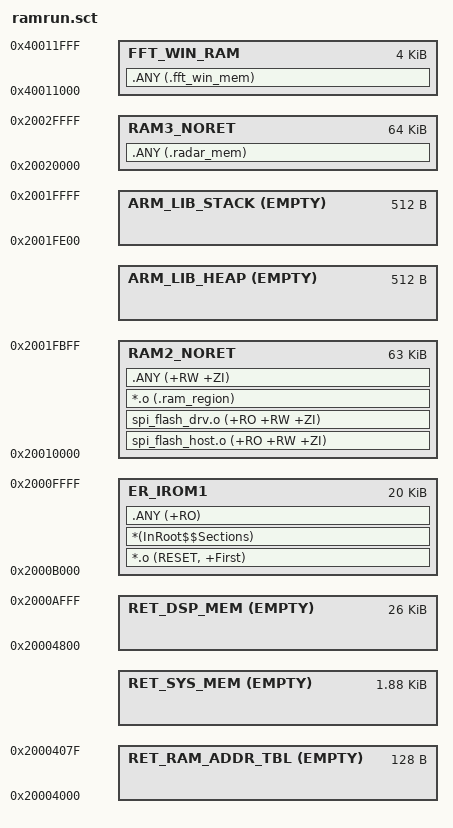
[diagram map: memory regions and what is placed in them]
#! armclang -E --target=arm-arm-none-eabi -mcpu=cortex-m0plus -xc
; *************************************************************
; *** Scatter-Loading Description File generated by uVision ***
; *************************************************************

#define STACK_SIZE        0x200
#define HEAP_SIZE         0x200

; SRAM0 0x2000_4000 -->   0x2000_8000 (ret_ram_tbl, SYS_MEM, DSP_MEM)
#define SRAM0_16KB_BASE   0x20004000
#define SRAM0_16KB_SIZE   0x4000

; 128 = 32*4, ret_ram_tbl can have 32 items at most
#define RET_RAM_TBL_BASE  SRAM0_16KB_BASE
#define RET_RAM_TBL_SIZE  128

#define RET_SYS_MEM_BASE  (RET_RAM_TBL_BASE + RET_RAM_TBL_SIZE)
#define RET_SYS_MEM_SIZE  (0x800 - RET_RAM_TBL_SIZE)

#define RET_DSP_MEM_BASE  0x20004800
#define RET_DSP_MEM_SIZE  0x6800

; SRAM1 0x2000_8000 -->   0x2001_0000 (Code)
#define FLASH_BASE        0x2000b000
#define FLASE_SIZE        0x00005000

; SRAM2 0x2001_0000 -->   0x2002_0000 (NO Retention, 64KB)
#define RAM2_NORET_BASE    0x20010000
#define RAM2_NORET_SIZE    0x00010000

; SRAM3 0x2002_0000 -->   0x2003_0000 (NO Retention, 64KB)
#define RAM3_NORET_BASE    0x20020000
#define RAM3_NORET_SIZE    0x00010000

; DSP FFT Win Rame (DSP occupies only)
#define FFT_WIN_BASE      0x40011000
#define FFT_WIN_SIZE      0x00001000

LR_IROM1 FLASH_BASE FLASE_SIZE  {    ; load region size_region
  ER_IROM1 FLASH_BASE FLASE_SIZE  {  ; load address = execution address
   *.o (RESET, +First)
   *(InRoot$$Sections)
   .ANY (+RO)
  }

  ; SRAM0
  RET_RAM_ADDR_TBL  RET_RAM_TBL_BASE  EMPTY  RET_RAM_TBL_SIZE {

  }

  RET_SYS_MEM  AlignExpr(+0, 4)  EMPTY  RET_SYS_MEM_SIZE {
  }

  RET_DSP_MEM  RET_DSP_MEM_BASE  EMPTY  RET_DSP_MEM_SIZE {
  }

  ; SRAM2
  RAM2_NORET RAM2_NORET_BASE  (RAM2_NORET_SIZE- HEAP_SIZE - STACK_SIZE) {
    spi_flash_host.o (+RO +RW +ZI)
    spi_flash_drv.o  (+RO +RW +ZI)
    *.o              (.ram_region)
    .ANY             (+RW +ZI)
  }

  ARM_LIB_HEAP AlignExpr(+0, 8) EMPTY HEAP_SIZE {  ; disable heap,if not use system heap
  }

  ARM_LIB_STACK (RAM2_NORET_BASE + RAM2_NORET_SIZE) EMPTY -STACK_SIZE {
  }

  ; SRAM3
  RAM3_NORET RAM3_NORET_BASE  RAM3_NORET_SIZE { ; radar only use the memory after 0x20010000
   .ANY (.radar_mem)
  }

  FFT_WIN_RAM  FFT_WIN_BASE FFT_WIN_SIZE {
   .ANY (.fft_win_mem)
  }
}
